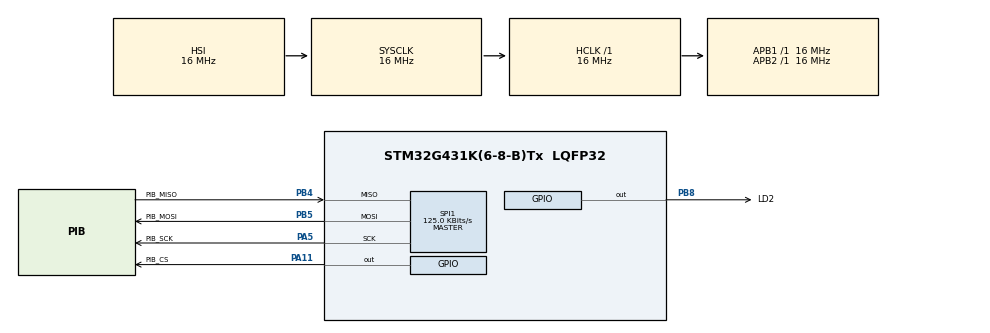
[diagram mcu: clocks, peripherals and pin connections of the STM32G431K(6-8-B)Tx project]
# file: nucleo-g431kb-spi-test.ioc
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Mcu.Family=STM32G4
Mcu.Name=STM32G431K(6-8-B)Tx
Mcu.Package=LQFP32
NVIC.PriorityGroup=NVIC_PRIORITYGROUP_4
PA11.GPIO_Label=PIB_CS
PA11.GPIO_Speed=GPIO_SPEED_FREQ_LOW
PA11.PinState=GPIO_PIN_SET
PA11.Signal=GPIO_Output
PA13.GPIO_Label=T_SWDIO
PA13.Mode=Serial_Wire
PA13.Signal=SYS_JTMS-SWDIO
PA14.GPIO_Label=T_SWCLK
PA14.Mode=Serial_Wire
PA14.Signal=SYS_JTCK-SWCLK
PA5.GPIO_Label=PIB_SCK
PA5.Mode=Full_Duplex_Master
PA5.Signal=SPI1_SCK
PB4.GPIO_Label=PIB_MISO
PB4.GPIO_PuPd=GPIO_PULLDOWN
PB4.Mode=Full_Duplex_Master
PB4.Signal=SPI1_MISO
PB5.GPIO_Label=PIB_MOSI
PB5.Mode=Full_Duplex_Master
PB5.Signal=SPI1_MOSI
PB8-BOOT0.GPIO_Label=LD2
PB8-BOOT0.Signal=GPIO_Output
ProjectManager.HeapSize=0x200
ProjectManager.StackSize=0x400
ProjectManager.TargetToolchain=STM32CubeIDE
RCC.ADC12Freq_Value=16000000
RCC.AHBFreq_Value=16000000
RCC.APB1Freq_Value=16000000
RCC.APB1TimFreq_Value=16000000
RCC.APB2Freq_Value=16000000
RCC.APB2TimFreq_Value=16000000
RCC.CortexFreq_Value=16000000
RCC.EXTERNAL_CLOCK_VALUE=12288000
RCC.HCLKFreq_Value=16000000
RCC.HSE_VALUE=8000000
RCC.HSI48_VALUE=48000000
RCC.HSI_VALUE=16000000
RCC.LSE_VALUE=32768
RCC.SYSCLKFreq_VALUE=16000000
RCC.USBFreq_Value=64000000
RCC.VCOOutputFreq_Value=128000000
SPI1.BaudRatePrescaler=SPI_BAUDRATEPRESCALER_128
SPI1.CLKPhase=SPI_PHASE_1EDGE
SPI1.CLKPolarity=SPI_POLARITY_LOW
SPI1.CRCCalculation=SPI_CRCCALCULATION_DISABLE
SPI1.CalculateBaudRate=125.0 KBits/s
SPI1.DataSize=SPI_DATASIZE_8BIT
SPI1.Direction=SPI_DIRECTION_2LINES
SPI1.FirstBit=SPI_FIRSTBIT_MSB
SPI1.GPIO_SPEED=GPIO_SPEED_FREQ_LOW
SPI1.Mode=SPI_MODE_MASTER
SPI1.NSS=SPI_NSS_SOFT
SPI1.NSSPMode=SPI_NSS_PULSE_DISABLE
SPI1.TIMode=SPI_TIMODE_DISABLE
SPI1.VirtualType=VM_MASTER
VP_SYS_VS_DBSignals.Mode=DisableDeadBatterySignals
board=custom

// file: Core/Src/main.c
/* USER CODE BEGIN Header */
/**
  ******************************************************************************
  * @file           : main.c
  * @brief          : Main program body
  ******************************************************************************
  * @attention
  *
  * Copyright (c) 2026 STMicroelectronics.
  * All rights reserved.
  *
  * This software is licensed under terms that can be found in the LICENSE file
  * in the root directory of this software component.
  * If no LICENSE file comes with this software, it is provided AS-IS.
  *
  ******************************************************************************
  */
/* USER CODE END Header */
#include "main.h"

/* USER CODE BEGIN Includes */
#include "spi_telemetry_test.h"
#include "spi_bridge.h"
/* USER CODE END Includes */

/* USER CODE BEGIN PD */
#define RUN_SPI_BRIDGE 1

/* USER CODE END PD */

SPI_HandleTypeDef hspi1;

void SystemClock_Config(void);
static void MX_GPIO_Init(void);
static void MX_SPI1_Init(void);

int main(void)
{

  /* MCU Configuration--------------------------------------------------------*/

  /* Reset of all peripherals, Initializes the Flash interface and the Systick. */
  HAL_Init();

  /* Configure the system clock */
  SystemClock_Config();

  /* Initialize all configured peripherals */
  MX_GPIO_Init();
  MX_SPI1_Init();
  /* USER CODE BEGIN 2 */
#if RUN_SPI_BRIDGE
  spi_bridge_init(&hspi1);
#else
  spi_test_init(&hspi1);
#endif
  /* USER CODE END 2 */

  /* Infinite loop */
  while (1)
  {

    /* USER CODE BEGIN 3 */
#if RUN_SPI_BRIDGE
    spi_bridge_run_once();
#else
    spi_test_run_once();
#endif
  }
  /* USER CODE END 3 */
}

void SystemClock_Config(void)
{
  RCC_OscInitTypeDef RCC_OscInitStruct = {0};
  RCC_ClkInitTypeDef RCC_ClkInitStruct = {0};

  /** Configure the main internal regulator output voltage
  */
  HAL_PWREx_ControlVoltageScaling(PWR_REGULATOR_VOLTAGE_SCALE1);

  /** Initializes the RCC Oscillators according to the specified parameters
  * in the RCC_OscInitTypeDef structure.
  */
  RCC_OscInitStruct.OscillatorType = RCC_OSCILLATORTYPE_HSI;
  RCC_OscInitStruct.HSIState = RCC_HSI_ON;
  RCC_OscInitStruct.HSICalibrationValue = RCC_HSICALIBRATION_DEFAULT;
  RCC_OscInitStruct.PLL.PLLState = RCC_PLL_NONE;
  if (HAL_RCC_OscConfig(&RCC_OscInitStruct) != HAL_OK)
  {
    Error_Handler();
  }

  /** Initializes the CPU, AHB and APB buses clocks
  */
  RCC_ClkInitStruct.ClockType = RCC_CLOCKTYPE_HCLK|RCC_CLOCKTYPE_SYSCLK
                              |RCC_CLOCKTYPE_PCLK1|RCC_CLOCKTYPE_PCLK2;
  RCC_ClkInitStruct.SYSCLKSource = RCC_SYSCLKSOURCE_HSI;
  RCC_ClkInitStruct.AHBCLKDivider = RCC_SYSCLK_DIV1;
  RCC_ClkInitStruct.APB1CLKDivider = RCC_HCLK_DIV1;
  RCC_ClkInitStruct.APB2CLKDivider = RCC_HCLK_DIV1;

  if (HAL_RCC_ClockConfig(&RCC_ClkInitStruct, FLASH_LATENCY_0) != HAL_OK)
  {
    Error_Handler();
  }
}

static void MX_SPI1_Init(void)
{

  /* SPI1 parameter configuration*/
  hspi1.Instance = SPI1;
  hspi1.Init.Mode = SPI_MODE_MASTER;
  hspi1.Init.Direction = SPI_DIRECTION_2LINES;
  hspi1.Init.DataSize = SPI_DATASIZE_8BIT;
  hspi1.Init.CLKPolarity = SPI_POLARITY_LOW;
  hspi1.Init.CLKPhase = SPI_PHASE_1EDGE;
  hspi1.Init.NSS = SPI_NSS_SOFT;
  hspi1.Init.BaudRatePrescaler = SPI_BAUDRATEPRESCALER_128;
  hspi1.Init.FirstBit = SPI_FIRSTBIT_MSB;
  hspi1.Init.TIMode = SPI_TIMODE_DISABLE;
  hspi1.Init.CRCCalculation = SPI_CRCCALCULATION_DISABLE;
  hspi1.Init.CRCPolynomial = 7;
  hspi1.Init.CRCLength = SPI_CRC_LENGTH_DATASIZE;
  hspi1.Init.NSSPMode = SPI_NSS_PULSE_DISABLE;
  if (HAL_SPI_Init(&hspi1) != HAL_OK)
  {
    Error_Handler();
  }

}

static void MX_GPIO_Init(void)
{
  GPIO_InitTypeDef GPIO_InitStruct = {0};

  /* GPIO Ports Clock Enable */
  __HAL_RCC_GPIOA_CLK_ENABLE();
  __HAL_RCC_GPIOB_CLK_ENABLE();

  /*Configure GPIO pin Output Level */
  HAL_GPIO_WritePin(PIB_CS_GPIO_Port, PIB_CS_Pin, GPIO_PIN_SET);

  /*Configure GPIO pin Output Level */
  HAL_GPIO_WritePin(LD2_GPIO_Port, LD2_Pin, GPIO_PIN_RESET);

  /*Configure GPIO pin : PIB_CS_Pin */
  GPIO_InitStruct.Pin = PIB_CS_Pin;
  GPIO_InitStruct.Mode = GPIO_MODE_OUTPUT_PP;
  GPIO_InitStruct.Pull = GPIO_NOPULL;
  GPIO_InitStruct.Speed = GPIO_SPEED_FREQ_LOW;
  HAL_GPIO_Init(PIB_CS_GPIO_Port, &GPIO_InitStruct);

  /*Configure GPIO pin : LD2_Pin */
  GPIO_InitStruct.Pin = LD2_Pin;
  GPIO_InitStruct.Mode = GPIO_MODE_OUTPUT_PP;
  GPIO_InitStruct.Pull = GPIO_NOPULL;
  GPIO_InitStruct.Speed = GPIO_SPEED_FREQ_LOW;
  HAL_GPIO_Init(LD2_GPIO_Port, &GPIO_InitStruct);

}

void Error_Handler(void)
{
  __disable_irq();
  while (1)
  {
  }
}
